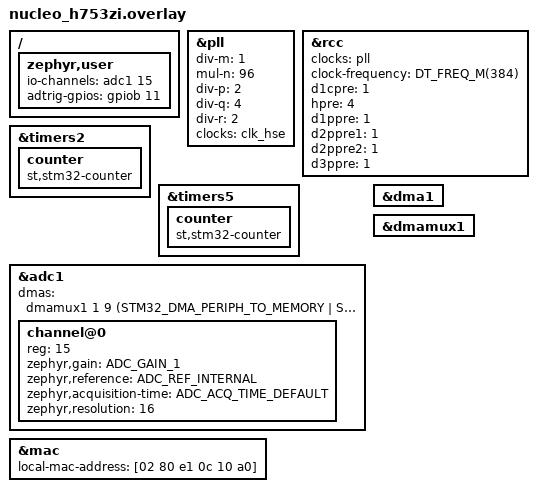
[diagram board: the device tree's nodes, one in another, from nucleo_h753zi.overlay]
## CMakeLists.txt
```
# SPDX-License-Identifier: Apache-2.0

cmake_minimum_required(VERSION 3.20.0)

find_package(Zephyr REQUIRED HINTS $ENV{ZEPHYR_BASE})
project(adunit)

target_include_directories(app PRIVATE src)
target_sources(app PRIVATE 
        src/adc_averaging_ctx.c
        src/adc_operation.c
        src/dummy_trigger.c
        src/enet_server.c
        src/gpio.c
        src/main.c)
```

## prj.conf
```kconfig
CONFIG_OUTPUT_DISASSEMBLY=y
CONFIG_OUTPUT_DISASSEMBLE_ALL=n

# Generic networking options
CONFIG_NETWORKING=y
CONFIG_NET_L2_ETHERNET=y
CONFIG_NET_IPV4=y
CONFIG_NET_IPV6=n
CONFIG_NET_UDP=y
CONFIG_NET_TCP=y
CONFIG_NET_SOCKETS=y
CONFIG_NET_SOCKETS_POSIX_NAMES=y
CONFIG_NET_CONFIG_MY_IPV4_ADDR="192.168.001.159"
CONFIG_NET_CONFIG_MY_IPV4_NETMASK="255.255.255.000"
CONFIG_NET_CONFIG_MY_IPV4_GW="192.168.001.001"
CONFIG_NET_DHCPV4=n
CONFIG_NET_CONFIG_SETTINGS=y
CONFIG_ETH_DRIVER=y
CONFIG_DMA_STM32=y

CONFIG_ADC_STM32_DMA=y
CONFIG_LOG=y
CONFIG_ADC=y
CONFIG_DMA=y
CONFIG_EVENTS=y

CONFIG_DMA=y
CONFIG_GPIO=y
CONFIG_COUNTER=y
CONFIG_COUNTER_TIMER_STM32=y
CONFIG_ADC_STM32=n
CONFIG_ADC_STM32_CUSTOM=y
CONFIG_COUNTER_RTC_STM32=y
```

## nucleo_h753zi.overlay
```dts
/* Copyright (c) 2021 STMicroelectronics
   SPDX-License-Identifier: Apache-2.0 */

 / {
	zephyr,user {
		/* adjust channel number according to pinmux in board.dts */
		io-channels = <&adc1 15>;
        adtrig-gpios = <&gpiob 11 GPIO_ACTIVE_HIGH>;
	};
};

&pll {
	div-m = <1>;
	mul-n = <96>;
	div-p = <2>;
	div-q = <4>;
	div-r = <2>;
	clocks = <&clk_hse>;
	status = "okay";
};

&rcc {
	clocks = <&pll>;
	clock-frequency = <DT_FREQ_M(384)>;
	d1cpre = <1>;
	hpre = <4>;
	d1ppre = <1>;
	d2ppre1 = <1>;
	d2ppre2 = <1>;
	d3ppre = <1>;
	status = "okay";
};

&timers2 {
	status = "okay";
	counter {
		compatible = "st,stm32-counter";
		status = "okay";
	};
};

&timers5 {
	status = "okay";
	counter {
		compatible = "st,stm32-counter";
		status = "okay";
	};
};

&adc1 {
	#address-cells = <1>;
	#size-cells = <0>;
	dmas = <&dmamux1 1 9 (STM32_DMA_PERIPH_TO_MEMORY | STM32_DMA_PERIPH_16BITS | STM32_DMA_MEM_16BITS)>;
    dma-names="adcdma";
	channel@0 {
		reg = <15>;
		zephyr,gain = "ADC_GAIN_1";
		zephyr,reference = "ADC_REF_INTERNAL";
		zephyr,acquisition-time = <ADC_ACQ_TIME_DEFAULT>;
		zephyr,resolution = <16>;
	};

};
&mac {
	local-mac-address = [02 80 e1 0c 10 a0];
};
&dma1 {
	status = "okay";
};
&dmamux1 {
	status = "okay";
};
```

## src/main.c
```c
/*
 * Copyright (c) 2016 Intel Corporation
 *
 * SPDX-License-Identifier: Apache-2.0
 */

#include <zephyr/device.h>
#include <zephyr/devicetree.h>
#include <zephyr/kernel.h>

#include "adc_operation.h"
#include "enet_server.h"

#define ADC_PRIORITY -7
#define ENET_PRIORITY 7
#define STACKSIZE 1024

K_THREAD_DEFINE(adc_id, STACKSIZE, adc_operation, NULL, NULL, NULL,
		ADC_PRIORITY, 0, 0);
K_THREAD_DEFINE(enet_id, STACKSIZE, enet_server, NULL, NULL, NULL,
		ENET_PRIORITY, 0, 0);
```

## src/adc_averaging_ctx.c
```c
#include <zephyr/kernel.h>
#include "adc_custom.h"
#include "adc_stm32_custom.h"

#define BUFLEN 57600
#define NUM_AVERAGES_DEFAULT 1

/* Global array declaration */
uint16_t buf[BUFLEN];
uint32_t buf_sum[BUFLEN];

struct adc_averaging_ctx avctx = {
	.buf_sum = buf_sum,
	.current_idx = 0,
	.num_averages = NUM_AVERAGES_DEFAULT,
	.remaining_count = NUM_AVERAGES_DEFAULT,
	.buf_size = sizeof(buf_sum),
	.start_flag = false,
};

struct adc_sequence_options options = {
	.extra_samplings = BUFLEN*NUM_AVERAGES_DEFAULT-1,
	.interval_us = 0U,
	.user_data = &avctx,	
};

struct adc_sequence sequence = {
	.options = &options,
	.buffer = buf,
	/* buffer size in bytes, not number of samples */
	.buffer_size = sizeof(buf),
};

void set_num_averages(uint16_t num_averages){
	avctx.num_averages = num_averages;
	avctx.remaining_count = num_averages;
	options.extra_samplings = BUFLEN*num_averages - 1;
}
```

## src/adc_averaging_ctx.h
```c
#pragma once

extern struct adc_averaging_ctx avctx;
extern struct adc_sequence_options options;
extern struct adc_sequence sequence;

void set_num_averages(uint16_t num_averages);
```

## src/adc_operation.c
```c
#include <stdio.h>
#include <zephyr/device.h>
#include <zephyr/devicetree.h>
#include <stm32_ll_adc.h>
#include <stm32_ll_gpio.h>
#include <stm32_ll_tim.h>
#include <zephyr/kernel.h>
#include <zephyr/drivers/gpio.h>
#include "adc_custom.h"
#include "adc_stm32_custom.h"
#include "adc_averaging_ctx.h"
#include "gpio.h"
#include "dummy_trigger.h"

#define AUTO_RELOAD_CNT_TIM2 99
#define PRESCALE_TIM2 99

/* define events */
K_EVENT_DEFINE(adc_events);

/* The devicetree node identifier for the "led0" alias. */
#define ADC_NODE DT_NODELABEL(adc1)
#define TIM2_NODE DT_NODELABEL(timers2)

/*
 * A build error on this line means your board is unsupported.
 * See the sample documentation for information on how to fix this.
 */

#if !DT_NODE_EXISTS(DT_PATH(zephyr_user)) || \
	!DT_NODE_HAS_PROP(DT_PATH(zephyr_user), io_channels)
#error "No suitable devicetree overlay specified"
#endif

#define DT_SPEC_AND_COMMA(node_id, prop, idx) \
	ADC_DT_SPEC_GET_BY_IDX(node_id, idx),

/* Data of ADC io-channels specified in devicetree. */
static const struct adc_dt_spec adc_channels[] = {
	DT_FOREACH_PROP_ELEM(DT_PATH(zephyr_user), io_channels,
			     DT_SPEC_AND_COMMA)
};

void initialize_peripherals(void){
	
	int err;
	ADC_TypeDef *adc;
	TIM_TypeDef *tim2;

	adc = (const struct ADC_TypeDef *)DT_REG_ADDR(ADC_NODE);
	tim2 = (const struct TIM_TypeDef *)DT_REG_ADDR(TIM2_NODE);
	
	// ADC Setting. Conversion Trigger from Timer2
	LL_ADC_REG_SetTriggerSource(adc, LL_ADC_REG_TRIG_EXT_TIM2_TRGO);
	LL_ADC_REG_SetTriggerEdge(adc, LL_ADC_REG_TRIG_EXT_RISING);

  	
	// Timer2 Setting. Conversion Frequency 9.6 kHz
	LL_TIM_SetAutoReload(tim2, AUTO_RELOAD_CNT_TIM2);
	LL_TIM_SetPrescaler(tim2, PRESCALE_TIM2);
	LL_TIM_SetTriggerOutput(tim2, LL_TIM_TRGO_UPDATE);
	LL_TIM_EnableCounter(tim2);
	
	enable_dummy_trigger();

	/* Configure channels individually prior to sampling. */
	for (size_t i = 0U; i < ARRAY_SIZE(adc_channels); i++) {
		if (!device_is_ready(adc_channels[i].dev)) {
			printk("ADC controller device %s not ready\n", adc_channels[i].dev->name);
			return 0;
		}
		err = adc_stm32_channel_setup(adc_channels[i].dev, &(adc_channels[i].channel_cfg));
		if (err < 0) {
			printk("Could not setup channel #%d (%d)\n", i, err);
			return 0;
		}
	}
	SCB_InvalidateDCache();
	gpio_init();
}

void adc_operation(void)
{
	
	int err;
	initialize_peripherals();
	
	while(1){
		k_event_wait(&adc_events, BIT(0), true, K_FOREVER);
		gpio_pin_set_dt(&led, 1);
		printk("Start ADC reading\n");
		gpio_pin_interrupt_configure_dt(&adtrg, GPIO_INT_EDGE_TO_ACTIVE);
		for (size_t i = 0U; i < ARRAY_SIZE(adc_channels); i++) {
			int32_t val_mv;
			(void)adc_sequence_init_dt(&adc_channels[i], &sequence);
			err = adc_stm32_read(adc_channels[i].dev, &sequence);
			if (err < 0) {
				printk("Could not read (%d)\n", err);
				continue;
			}
		}
		gpio_pin_interrupt_configure_dt(&adtrg, GPIO_INT_DISABLE);
		avctx.start_flag = false;
		gpio_pin_set_dt(&led, 0);
	}

}
```

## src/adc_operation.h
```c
#pragma once
extern struct k_event adc_events;

void adc_operation(void);
```

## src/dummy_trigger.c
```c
#include <stm32_ll_gpio.h>
#include <stm32_ll_tim.h>

#include <zephyr/kernel.h>
#include <zephyr/device.h>
#include <zephyr/devicetree.h>

#define AUTO_RELOAD_CNT_TIM5 999999
#define PRESCALE_TIM5 95

#define COMPARE_VALUE_TIM5 999999

#define GPIOA_NODE DT_NODELABEL(gpioa)
#define TIM5_NODE DT_NODELABEL(timers5)

void enable_dummy_trigger(){

    TIM_TypeDef *tim5;
	GPIO_TypeDef *gpioa;

	tim5 = (const struct TIM_TypeDef *)DT_REG_ADDR(TIM5_NODE);
	gpioa = (const struct GPIO_TypeDef *)DT_REG_ADDR(GPIOA_NODE);

    // 1 Hz DUMMY TRIGGER (TEST USAGE) 
	LL_GPIO_SetPinMode(gpioa, LL_GPIO_PIN_0, LL_GPIO_MODE_ALTERNATE);
	LL_GPIO_SetPinOutputType(gpioa, LL_GPIO_PIN_0, LL_GPIO_OUTPUT_PUSHPULL);
	LL_GPIO_SetAFPin_0_7(gpioa, LL_GPIO_PIN_0, LL_GPIO_AF_2);
	LL_TIM_SetAutoReload(tim5, AUTO_RELOAD_CNT_TIM5);
	LL_TIM_SetPrescaler(tim5, PRESCALE_TIM5);
	LL_TIM_CC_EnableChannel(tim5, LL_TIM_CHANNEL_CH1);
	LL_TIM_OC_SetCompareCH1(tim5, COMPARE_VALUE_TIM5);
	LL_TIM_OC_SetMode(tim5, LL_TIM_CHANNEL_CH1, LL_TIM_OCMODE_PWM1);
	LL_TIM_OC_SetPolarity(tim5, LL_TIM_CHANNEL_CH1, LL_TIM_OCPOLARITY_LOW);
	LL_TIM_EnableCounter(tim5);

}
```

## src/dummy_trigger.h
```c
#pragma once
void enable_dummy_trigger();
```

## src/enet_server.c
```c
#include <stdio.h>
#include <zephyr/kernel.h>
#include <zephyr/net/socket.h>
#include "adc_stm32_custom.h"
#include "adc_averaging_ctx.h"
#include "adc_operation.h"

#define BIND_PORT 10000

uint8_t cmd_buf[3];
uint16_t data;
uint8_t tmp_buf[3000];

static const uint8_t kCmdReadCh1[3]   = {0x70, 0x00, 0x21};
static const uint8_t kCmdReadCh2[3]   = {0x70, 0x00, 0x22};
static const uint8_t kCmdNumAvg[3]    = {0x70, 0x00, 0x71};
static const uint8_t kCmdRemaining[3] = {0x70, 0x00, 0x72};
static const uint8_t kCmdAverage[3]   = {0x70, 0x00, 0x73};
static const uint8_t kCmdOffset[3]    = {0x70, 0x00, 0x74};
static const uint8_t kCmdReset[3]     = {0x70, 0x00, 0x75};

static const uint8_t kRspReadCh1[3]   = {0x80, 0x00, 0x21};
static const uint8_t kRspReadCh2[3]   = {0x80, 0x00, 0x22};
static const uint8_t kRspNumAvg[3]    = {0x80, 0x00, 0x71};
static const uint8_t kRspRemaining[3] = {0x80, 0x00, 0x72};
static const uint8_t kRspAverage[3]   = {0x80, 0x00, 0x73};
static const uint8_t kRspOffset[3]    = {0x80, 0x00, 0x74};
static const uint8_t kRspReset[3]     = {0x80, 0x00, 0x75};

static const uint8_t kRspBusy[3]    = {0xf1, 0xff, 0x80};

static const float default_offset = 524288.0f;

static float offset = 524288.0f;

void send_data(int client, void *buf, size_t size) {
    size_t total_sent = 0;
	while (total_sent < size) {
		ssize_t sent = send(client, (char *)buf + total_sent, size - total_sent, 0);
		if (sent < 0) {
			printk("Error sending data\n");
			break;
		}
		total_sent += sent;
	}
}

void send_waveform(int client) {
    size_t buf_index = 0;
    size_t buf_size = avctx.buf_size / sizeof(avctx.buf_sum[0]);
    float inv_num_averages = 1.0f / (float)avctx.num_averages;

    for (int i = 0; i < buf_size; i++) {
        float val_start = avctx.buf_sum[i] * inv_num_averages;
        float val_end = (i == buf_size - 1) ? val_start : avctx.buf_sum[i + 1] * inv_num_averages;
        float delta = (val_end - val_start) * 0.1f;

        for (int j = 0; j < 10; j++) {
            int val = -(int)((val_start + delta * j) * 16.0f - offset);  // "-" due to inveted amplifier
            tmp_buf[buf_index] = val & 0x0000ff;
            tmp_buf[buf_index + 1] = (val & 0x00ff00) >> 8;
            tmp_buf[buf_index + 2] = (val & 0xff0000) >> 16;
            buf_index += 3;

            if (buf_index >= sizeof(tmp_buf)) {
                send_data(client, (void*)tmp_buf, buf_index);
                buf_index = 0;
            }
        }
    }
    if (buf_index > 0) {
        send_data(client, (void*)tmp_buf, buf_index);
    }
    tmp_buf[0] = 0xff;
    tmp_buf[1] = 0xff;
    tmp_buf[2] = 0xff;
    send_data(client, (void*)tmp_buf, 3);
}
    

bool check_cmd(uint8_t set[3]) {
    for (int i = 0; i < 3; i++) {
        if (set[i] != cmd_buf[i]) {
            return false;
        }
    }
    return true;
}

float cal_offset(unsigned int num_averages) {
    if(avctx.buf_sum[0]==0.0f) return default_offset;
    unsigned int cnt = 0;
    float sum = 0;
    unsigned int prev;
    unsigned int len = avctx.buf_size/sizeof(avctx.buf_sum[0]);
    
    for(unsigned int i=0;i<len;i++){
        if(avctx.buf_sum[i]==0.0f){ 
            sum -= (float)prev; 
            cnt--;
            break;
        }
        sum += (float)avctx.buf_sum[i];
        prev = avctx.buf_sum[i];
        cnt++;
    }
    return (sum/((float)cnt)/((float)num_averages))*16;

}

void handle_client_commands(int client) {
    static unsigned int num_averages_offset = 1;
    static bool offset_done = false;
    while (1) {
        ssize_t len = recv(client, cmd_buf, 3, 0);
        if (len == 0) {
            close(client);
            break;
        }

        if (check_cmd(kCmdRemaining)) {
            send(client, kRspRemaining, 3, 0);
            send(client, (uint8_t*)&avctx.remaining_count, 2, 0);
            continue;
        }

        if (k_event_test(&adc_events, BIT(0))) {
            send(client, kRspBusy, 3, 0);
            continue;
        }

        if (check_cmd(kCmdReadCh1)) {
            printk("test\n");
            recv(client, tmp_buf, 3, 0);
            printk("required num data = %d\n", (tmp_buf[2]<<16)|(tmp_buf[1]<<8)|tmp_buf[0]);
            send(client, kRspReadCh1, 3, 0);
            send_waveform(client);
            continue;
        }

        if (check_cmd(kCmdReadCh2)) {
            recv(client, tmp_buf, 3, 0);
            printk("required num data = %d\n", (tmp_buf[2]<<16)|(tmp_buf[1]<<8)|tmp_buf[0]);
            send(client, kRspReadCh2, 3, 0);
            send_waveform(client);
            continue;
        }

        if (check_cmd(kCmdNumAvg)) {
            recv(client, (uint8_t*)&data, 2, 0);
            set_num_averages(data);
            printk("num averages = %d\n", avctx.num_averages);
            send(client, kRspNumAvg, 3, 0);
            send(client, (uint8_t*)(&(avctx.num_averages)), sizeof(avctx.num_averages), 0);
            continue;
        }

        if (check_cmd(kCmdAverage)) {
            send(client, kRspAverage, 3, 0);
            if(!offset_done){
                offset = cal_offset(num_averages_offset);
                offset_done = true;
                printk("offset = %d\n",(int)offset);
            }
            memset(avctx.buf_sum, 0, avctx.buf_size);
            avctx.remaining_count = avctx.num_averages;
            k_event_set(&adc_events, BIT(0)); // Trigger ADC start event
            continue;
        }

        if (check_cmd(kCmdOffset)) {
            send(client, kRspOffset, 3, 0);
            memset(avctx.buf_sum, 0, avctx.buf_size);
            avctx.remaining_count = avctx.num_averages;
            num_averages_offset = avctx.num_averages;
            k_event_set(&adc_events, BIT(0)); // Trigger ADC start event
            continue;
        }

        if (check_cmd(kCmdReset)) {
            avctx.remaining_count = avctx.num_averages;
            send(client, kRspReset, 3, 0);
            continue;
        }
    }
}

void enet_server(void) {
    int sockfd = socket(AF_INET, SOCK_STREAM, IPPROTO_TCP);
    struct sockaddr_in addr = {.sin_family = AF_INET, .sin_port = htons(BIND_PORT), .sin_addr.s_addr = htonl(INADDR_ANY)};
    bind(sockfd, (struct sockaddr *)&addr, sizeof(addr));
    listen(sockfd, 1);
    while (1) {
        int client = accept(sockfd, NULL, NULL);
        handle_client_commands(client);
    }
}
```

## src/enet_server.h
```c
#pragma once

void enet_server(void);
```

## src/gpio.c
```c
#include <stm32_ll_gpio.h>
#include <zephyr/kernel.h>
#include <zephyr/drivers/gpio.h>
#include "adc_stm32_custom.h"
#include "adc_averaging_ctx.h"

#define LED0_NODE DT_ALIAS(led0)

const struct gpio_dt_spec led = GPIO_DT_SPEC_GET(LED0_NODE, gpios);
const struct gpio_dt_spec adtrg = GPIO_DT_SPEC_GET(DT_PATH(zephyr_user), adtrig_gpios);
static struct gpio_callback adtrg_cb_data;

void isr_trigger_detection(const struct device *dev, struct gpio_callback *cb,
		    uint32_t pins)
{
	if(avctx.start_flag == false)
		avctx.start_flag = true;
	else 
		avctx.remaining_count = avctx.remaining_count - 1;
	//printk("remaining_cnt = %d, current_idx = %d\n", avctx.remaining_count, avctx.current_idx);
	avctx.current_idx = 0;
}

int gpio_init(){
    int err;
    
    if (!gpio_is_ready_dt(&led)) {
		return 0;
	}

	err = gpio_pin_configure_dt(&led, GPIO_OUTPUT_ACTIVE);
	if (err < 0) {
		return 0;
	}
	
    gpio_pin_set_dt(&led, 0); 
    
    if (!gpio_is_ready_dt(&adtrg)) {
		return 0;
	}

    err = gpio_pin_configure_dt(&adtrg, GPIO_INPUT);
	if (err < 0) {
		return 0;
	}
	
	err = gpio_pin_interrupt_configure_dt(&adtrg,
					      GPIO_INT_DISABLE);
	if (err != 0) {
		printk("Error %d: failed to configure interrupt on %s pin %d\n",
			err, adtrg.port->name, adtrg.pin);
		return 0;
	}
	
    gpio_init_callback(&adtrg_cb_data, isr_trigger_detection, BIT(adtrg.pin));
	gpio_add_callback(adtrg.port, &adtrg_cb_data);
    
	return 0;
}
```

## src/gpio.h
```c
#pragma once

extern const struct gpio_dt_spec led;
extern const struct gpio_dt_spec adtrg;

void isr_trigger_detection(const struct device *dev, struct gpio_callback *cb, uint32_t pins);
int gpio_init();
```
